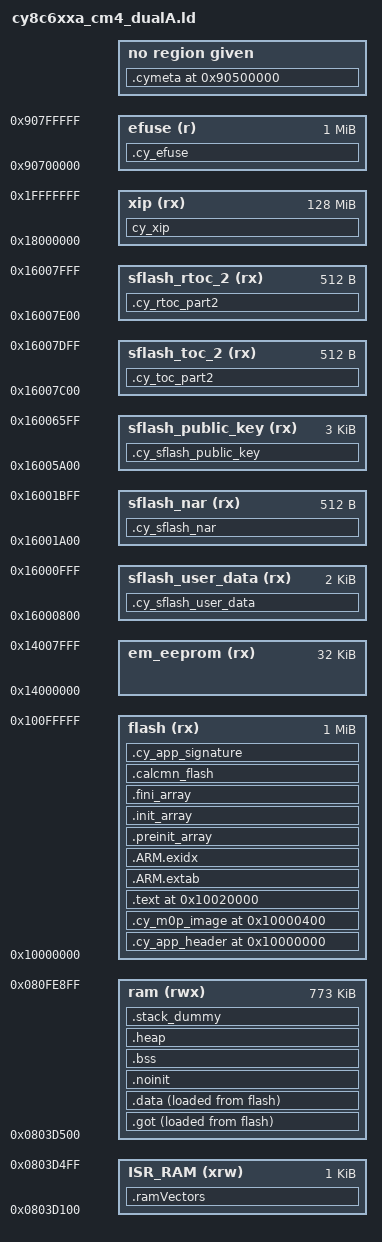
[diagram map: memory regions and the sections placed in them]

/**       ___
 *   ___ / _ \
 *  / _ ' (_) |       __  _
 * | (_) ,___/       / _|(_)
 *  \___/  _  _ __  | |_  _  _ __    ___  _ __  __ _
 *        | || '_ \ |  _|| || '_ \  / _ \| '__|/ _' |
 *        | || | | || |  | || | | ||  __/| |  | (_| |
 *        |_||_| |_||_|  |_||_| |_| \___||_|   \__,_|
 *
 * @file cy8c6xxa_cm4_dualA.ld            @brief linker script
 *
 * @author Autogenerated
 *
 * @copyright 2023 Infinera. All rights reserved.
 * Infinera Proprietary and Confidential.
 *
 * @details
 * This file was generated automatically, src cy8c6xxa_cm4_dualA.ld.in for details
 * Please do not modify it manually
 *
 ***************************************************************************/

OUTPUT_FORMAT ("elf32-littlearm", "elf32-bigarm", "elf32-littlearm")
SEARCH_DIR(.)
GROUP(-lgcc -lc -lnosys)
ENTRY(Reset_Handler)


STACK_SIZE = 0x1000;
EXTERN(Reset_Handler)




MEMORY
{







    ISR_RAM (xrw) : ORIGIN = 0x0803D100, LENGTH = 0x400
    ram (rwx) : ORIGIN = 0x0803D500, LENGTH = 0xC1400
    flash (rx) : ORIGIN = (0x10000000), LENGTH = ((0x200000) / 2)






    em_eeprom (rx) : ORIGIN = 0x14000000, LENGTH = 0x8000


    sflash_user_data (rx) : ORIGIN = 0x16000800, LENGTH = 0x800
    sflash_nar (rx) : ORIGIN = 0x16001A00, LENGTH = 0x200
    sflash_public_key (rx) : ORIGIN = 0x16005A00, LENGTH = 0xC00
    sflash_toc_2 (rx) : ORIGIN = 0x16007C00, LENGTH = 0x200
    sflash_rtoc_2 (rx) : ORIGIN = 0x16007E00, LENGTH = 0x200
    xip (rx) : ORIGIN = 0x18000000, LENGTH = 0x8000000
    efuse (r) : ORIGIN = 0x90700000, LENGTH = 0x100000
}
__flash_begin = ORIGIN(flash) + 0x20000;
__flash_end = ORIGIN(flash) + (LENGTH(flash) - 0x20000) ;


GROUP(libgcc.a libc.a libm.a libnosys.a)
__cy_boot_signature_size = 256;
__cy_app_verify_start = ORIGIN(flash);
__cy_app_verify_length = LENGTH(flash) - __cy_boot_signature_size;

SECTIONS
{
    .cy_app_header ORIGIN (flash):
    {
        KEEP(*(.cy_app_header))
    } > flash


    .cy_m0p_image ORIGIN(flash) + 0x400 :
    {
        . = ALIGN(4);
        __cy_m0p_code_start = . ;
        KEEP(*(.cy_m0p_image))
        __cy_m0p_code_end = . ;
    } > flash


    ASSERT(__cy_m0p_code_end <= ORIGIN(flash) + 0x20000, "CM0+ flash image overflows with CM4, increase FLASH_CM0P_SIZE")


    .text ORIGIN(flash) + 0x20000 :
    {
        . = ALIGN(4);
        __flash_vector_table_begin = . ;
        KEEP(*(.vectors))
        __flash_vector_table_end = . ;

        *(.text*)

        KEEP(*(.init))
        KEEP(*(.fini))


        *crtbegin.o(.ctors)
        *crtbegin?.o(.ctors)
        *(EXCLUDE_FILE(*crtend?.o *crtend.o) .ctors)
        *(SORT(.ctors.*))
        *(.ctors)


        *crtbegin.o(.dtors)
        *crtbegin?.o(.dtors)
        *(EXCLUDE_FILE(*crtend?.o *crtend.o) .dtors)
        *(SORT(.dtors.*))
        *(.dtors)


        *(.rodata .rodata.* .constdata .constdata.* .conststring .conststring.*)

        KEEP(*(.eh_frame*))
        _etext = .;
    } > flash

    .ramVectors (NOLOAD) : ALIGN(8)
    {
        __ram_vector_table_begin = .;
        KEEP(*(.vectors))
        __ram_vector_table_end = .;
    } >ISR_RAM


    .got :
    {
        . = ALIGN(4);
        *(.got)
        *(.plt)
        *(.got.plt)
        KEEP(*(.igot.plt))
        . = ALIGN(4);
    } >ram AT > flash
    __flash_global_offset_table_begin = LOADADDR(.got) ;
    __flash_global_offset_table_end = __flash_global_offset_table_begin + SIZEOF(.got) ;
    __ram_global_offset_table_begin = ADDR(.got) ;
    __ram_global_offset_table_end = __ram_global_offset_table_begin + SIZEOF(.got) ;


    .ARM.extab :
    {
        . = ALIGN(4);
        *(.ARM.extab* .gnu.linkonce.armextab.*)
        . = ALIGN(4);
    } > flash

    .ARM.exidx :
    {
        . = ALIGN(4);
        __exidx_start = .;
        *(.ARM.exidx* .gnu.linkonce.armexidx.*)
        __exidx_end = .;
    } > flash

    .preinit_array :
    {
         . = ALIGN(4);
    KEEP (*(.preinit_array*))
    KEEP (*(.preinit_array*))
    PROVIDE_HIDDEN (__preinit_array_end = .);
        KEEP (*(.preinit_array*))
    PROVIDE_HIDDEN (__preinit_array_end = .);
        . = ALIGN(4);
    } > flash
    __preinit_array_start = LOADADDR(.preinit_array);
    __preinit_array_end = __preinit_array_start + SIZEOF(.preinit_array);



  .init_array :
  {
    . = ALIGN(4);
    KEEP (*(SORT(.init_array.*)))
    KEEP (*(.init_array*))
    . = ALIGN(4);
  } > flash
   __init_array_start = LOADADDR(.init_array);
   __init_array_end = __init_array_start + SIZEOF(.init_array);



  .fini_array :
  {
    . = ALIGN(4);
    KEEP (*(SORT(.fini_array.*)))
    KEEP (*(.fini_array*))
    . = ALIGN(4);
  } > flash
  __fini_array_start = LOADADDR(.fini_array) ;
  __fini_array_end = __fini_array_start + SIZEOF(.fini_array) ;





    .data :
    {
        . = ALIGN(4);
        __data_start__ = .;

        *(vtable)
        *(.data*)

        . = ALIGN(4);
        KEEP(*(.jcr*))
        . = ALIGN(4);

        KEEP(*(.cy_ramfunc*))
        . = ALIGN(4);

        __data_end__ = .;

    } > ram AT>flash
    _sidata = LOADADDR(.data);


    FLASH_CALCMN_START_ADDRESS = (0x10000000) + (0xDB800);
    .calcmn_flash FLASH_CALCMN_START_ADDRESS :
    {
        BYTE(0xDE);
        BYTE(0xC0);
        BYTE(0xAD);
        BYTE(0xDE);

        BYTE(0xDE);
        BYTE(0xC0);
        BYTE(0xAD);
        BYTE(0xDE);

        BYTE(0xDE);
        BYTE(0xC0);
        BYTE(0xAD);
        BYTE(0xDE);

        BYTE(0xDE);
        BYTE(0xC0);
        BYTE(0xAD);
        BYTE(0xDE);
       KEEP(*(.calcmn_flash));
    } > flash




    .noinit (NOLOAD) : ALIGN(8)
    {
      KEEP(*(.noinit))
    } > ram
    .bss (NOLOAD):
    {
        . = ALIGN(4);
        __bss_start__ = .;
        *(.bss*)
        *(COMMON)
        . = ALIGN(4);
        __bss_end__ = .;
    } > ram


    .heap (NOLOAD):
    {
        __HeapBase = .;
        __end__ = .;
        end = __end__;
        KEEP(*(.heap*))
        . = ORIGIN(ram) + LENGTH(ram) - STACK_SIZE;
        __HeapLimit = .;
    } > ram





    .stack_dummy (NOLOAD):
    {
        KEEP(*(.stack*))
    } > ram




    __StackTop = ORIGIN(ram) + LENGTH(ram);
    __StackLimit = __StackTop - SIZEOF(.stack_dummy);
    PROVIDE(__stack = __StackTop);


    ASSERT(__StackLimit >= __HeapLimit, "region RAM overflowed with stack")




    .cy_app_signature FLASH_CALCMN_START_ADDRESS - __cy_boot_signature_size :
    {
        KEEP(*(.cy_app_signature))
    } > flash


    .cy_sflash_user_data :
    {
        KEEP(*(.cy_sflash_user_data))
    } > sflash_user_data



    .cy_sflash_nar :
    {
        KEEP(*(.cy_sflash_nar))
    } > sflash_nar



    .cy_sflash_public_key :
    {
        KEEP(*(.cy_sflash_public_key))
    } > sflash_public_key



    .cy_toc_part2 :
    {
        KEEP(*(.cy_toc_part2))
    } > sflash_toc_2



    .cy_rtoc_part2 :
    {
        KEEP(*(.cy_rtoc_part2))
    } > sflash_rtoc_2





    cy_xip :
    {
        __cy_xip_start = .;
        KEEP(*(.cy_xip))
        __cy_xip_end = .;
    } > xip



    .cy_efuse :
    {
        KEEP(*(.cy_efuse))
    } > efuse





    .cymeta 0x90500000 : { KEEP(*(.cymeta)) } :NONE
}




__cy_memory_0_start = (0x10000000);
__cy_memory_0_length = 0x00100000;
__cy_memory_0_row_size = 0x200;


__cy_memory_1_start = 0x14000000;
__cy_memory_1_length = 0x8000;
__cy_memory_1_row_size = 0x200;


__cy_memory_2_start = 0x16000000;
__cy_memory_2_length = 0x8000;
__cy_memory_2_row_size = 0x200;


__cy_memory_3_start = 0x18000000;
__cy_memory_3_length = 0x08000000;
__cy_memory_3_row_size = 0x200;


__cy_memory_4_start = 0x90700000;
__cy_memory_4_length = 0x100000;
__cy_memory_4_row_size = 1;
